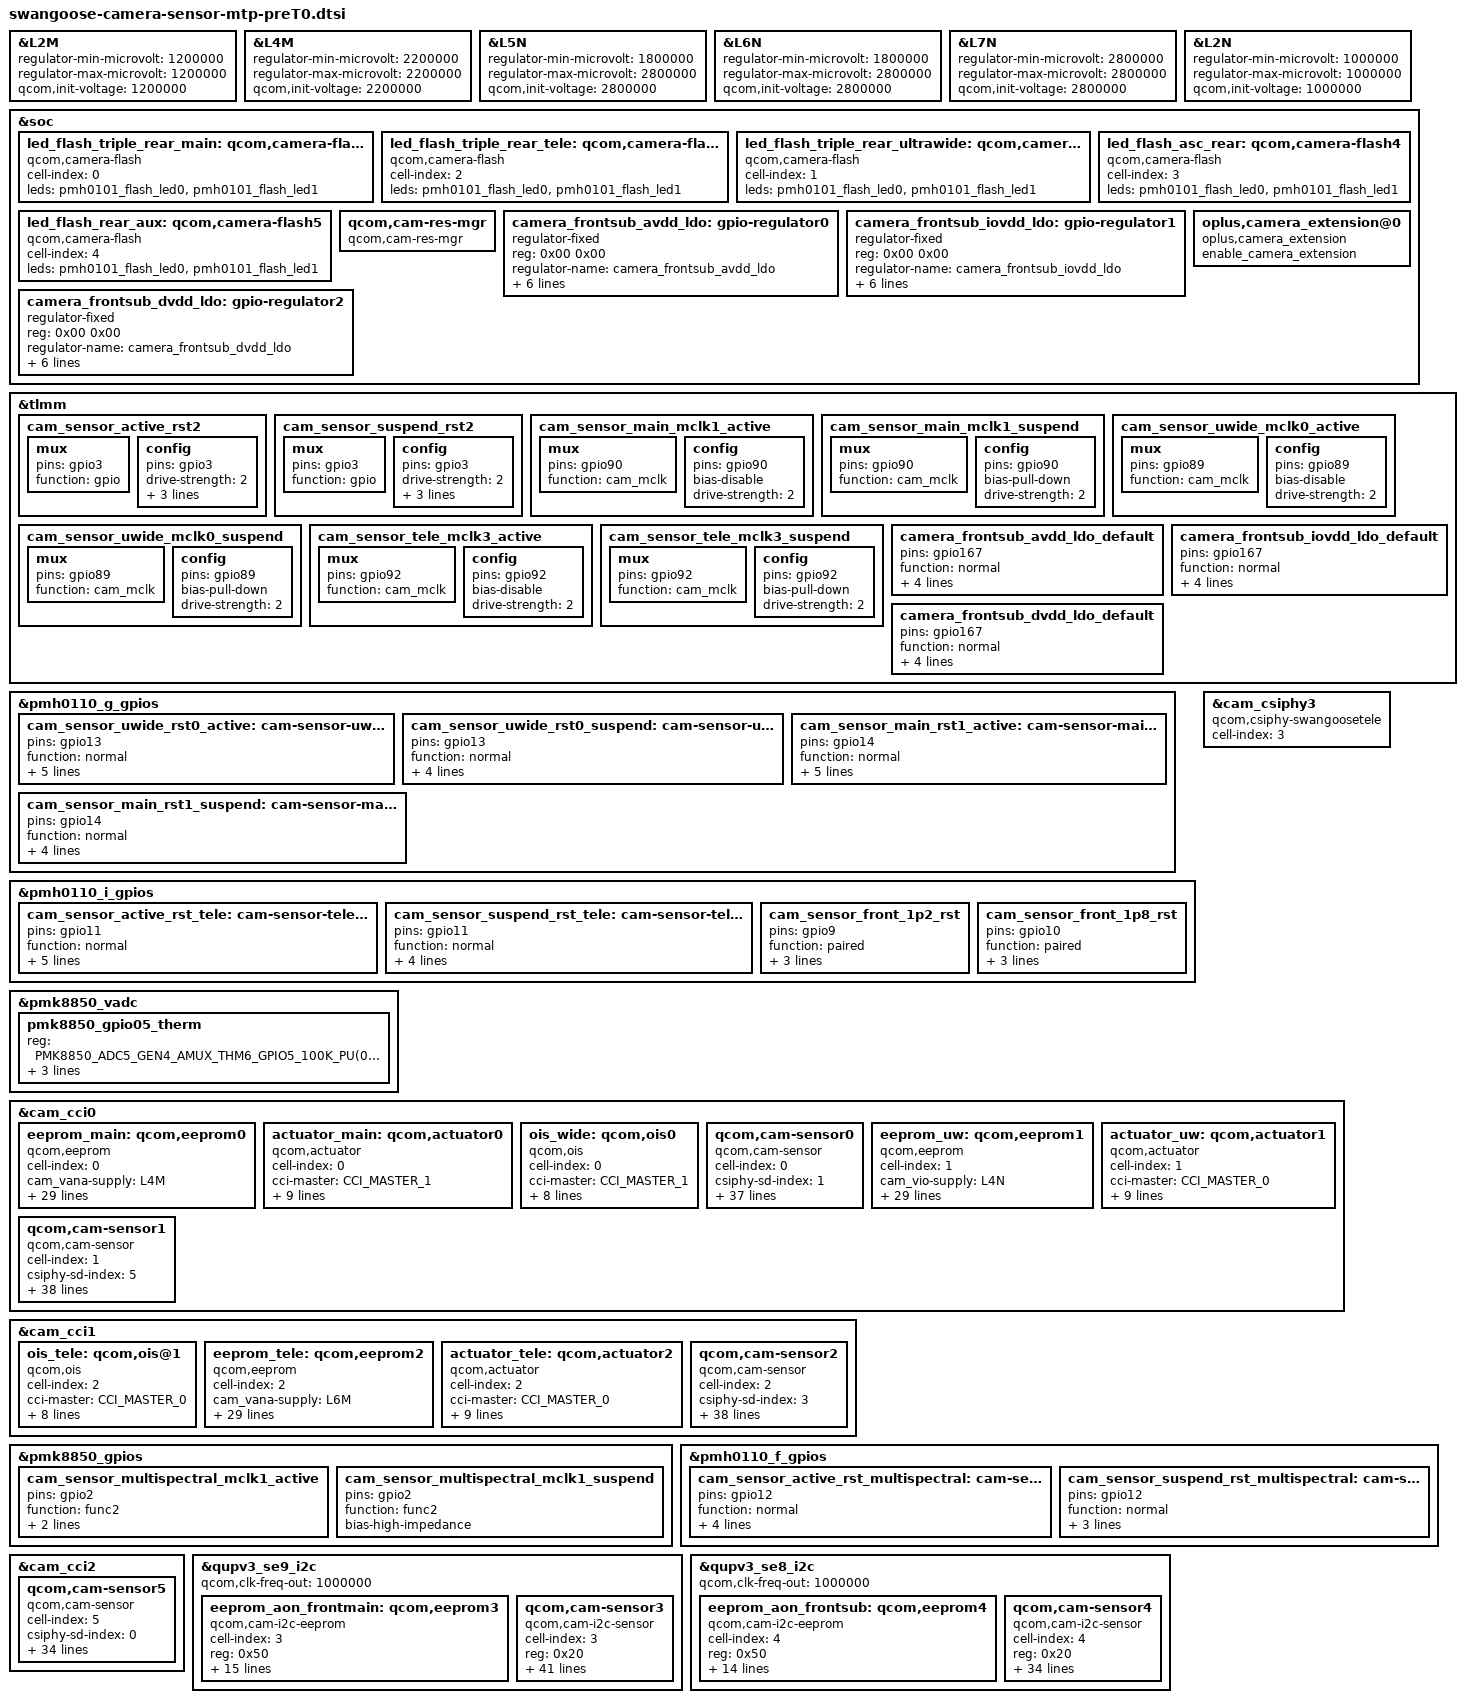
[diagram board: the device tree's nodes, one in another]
// SPDX-License-Identifier: BSD-3-Clause
/*
 * Copyright (c) 2024 Qualcomm Innovation Center, Inc. All rights reserved.
 */

#include <dt-bindings/msm-camera.h>
#include "ftm_camera_settings.dtsi"
#include <dt-bindings/iio/qcom,spmi-vadc.h>
#include <dt-bindings/iio/qcom,spmi-adc5-gen4-pmk8850.h>
#define PMK8850_SID  0

&L2M {
	regulator-min-microvolt = <1200000>;
	regulator-max-microvolt = <1200000>;
	qcom,init-voltage = <1200000>;
};

&L4M {
	regulator-min-microvolt = <2200000>;
	regulator-max-microvolt = <2200000>;
	qcom,init-voltage = <2200000>;
};

&L5N {
	regulator-min-microvolt = <1800000>;
	regulator-max-microvolt = <2800000>;
	qcom,init-voltage = <2800000>;
};

&L6N {
	regulator-min-microvolt = <1800000>;
	regulator-max-microvolt = <2800000>;
	qcom,init-voltage = <2800000>;
};

&L7N {
	regulator-min-microvolt = <2800000>;
	regulator-max-microvolt = <2800000>;
	qcom,init-voltage = <2800000>;
};

&L2N {
	regulator-min-microvolt = <1000000>;
	regulator-max-microvolt = <1000000>;
	qcom,init-voltage = <1000000>;
};

&soc {

	led_flash_triple_rear_main: qcom,camera-flash1 {
		cell-index = <0>;
		compatible = "qcom,camera-flash";
		leds = <&pmh0101_flash_led0 &pmh0101_flash_led1>;
		status = "ok";
	};

	led_flash_triple_rear_tele: qcom,camera-flash2 {
		cell-index = <2>;
		compatible = "qcom,camera-flash";
		leds = <&pmh0101_flash_led0 &pmh0101_flash_led1>;
		status = "ok";
	};

	led_flash_triple_rear_ultrawide: qcom,camera-flash3 {
		cell-index = <1>;
		compatible = "qcom,camera-flash";
		leds = <&pmh0101_flash_led0 &pmh0101_flash_led1>;
		status = "ok";
	};

	led_flash_asc_rear: qcom,camera-flash4 {
		cell-index = <3>;
		compatible = "qcom,camera-flash";
		leds = <&pmh0101_flash_led0 &pmh0101_flash_led1>;
		status = "ok";
	};

	led_flash_rear_aux: qcom,camera-flash5 {
		cell-index = <4>;
		compatible = "qcom,camera-flash";
		leds = <&pmh0101_flash_led0 &pmh0101_flash_led1>;
		status = "ok";
	};

	qcom,cam-res-mgr {
		compatible = "qcom,cam-res-mgr";
		status = "ok";
	};

	camera_frontsub_avdd_ldo: gpio-regulator0 {
		compatible = "regulator-fixed";
		reg = <0x00 0x00>;
		regulator-name = "camera_frontsub_avdd_ldo";
		regulator-min-microvolt = <2800000>;
		regulator-max-microvolt = <2800000>;
		regulator-enable-ramp-delay = <135>;
		enable-active-high;
		gpio = <&tlmm 167 0>;
		pinctrl-names = "default";
		pinctrl-0 = <&camera_frontsub_avdd_ldo_default>;
	};

	camera_frontsub_iovdd_ldo: gpio-regulator1 {
		compatible = "regulator-fixed";
		reg = <0x00 0x00>;
		regulator-name = "camera_frontsub_iovdd_ldo";
		regulator-min-microvolt = <1800000>;
		regulator-max-microvolt = <1800000>;
		regulator-enable-ramp-delay = <135>;
		enable-active-high;
		gpio = <&tlmm 167 0>;
		pinctrl-names = "default";
		pinctrl-0 = <&camera_frontsub_iovdd_ldo_default>;
	};

	camera_frontsub_dvdd_ldo: gpio-regulator2 {
		compatible = "regulator-fixed";
		reg = <0x00 0x00>;
		regulator-name = "camera_frontsub_dvdd_ldo";
		regulator-min-microvolt = <1050000>;
		regulator-max-microvolt = <1050000>;
		regulator-enable-ramp-delay = <135>;
		enable-active-high;
		gpio = <&tlmm 167 0>;
		pinctrl-names = "default";
		pinctrl-0 = <&camera_frontsub_dvdd_ldo_default>;
	};

	oplus,camera_extension@0 {
		compatible = "oplus,camera_extension";
		enable_camera_extension;
		status = "ok";
	};

};

&tlmm {

	cam_sensor_active_rst2: cam_sensor_active_rst2 {
		mux {
			pins = "gpio3";
			function = "gpio";
		};

		config {
			pins = "gpio3";
			drive-strength = <2>; /* 2 MA */
			bias-pull-down; /* PULL DOWN*/
			input-enable;
			qcom,apps;
		};
	};

	cam_sensor_suspend_rst2: cam_sensor_suspend_rst2 {
		mux {
			pins = "gpio3";
			function = "gpio";
		};

		config {
			pins = "gpio3";
			drive-strength = <2>; /* 2 MA */
			bias-pull-down; /* PULL DOWN*/
			input-enable;
			qcom,apps;
		};
	};

	cam_sensor_main_mclk1_active: cam_sensor_main_mclk1_active {
		/* MCLK1 */
		mux {
			pins = "gpio90";
			function = "cam_mclk";
		};

		config {
			pins = "gpio90";
			bias-disable; /* No PULL */
			drive-strength = <2>; /* 4 MA */
		};
	};

	cam_sensor_main_mclk1_suspend: cam_sensor_main_mclk1_suspend {
		/* MCLK1 */
		mux {
			pins = "gpio90";
			function = "cam_mclk";
		};

		config {
			pins = "gpio90";
			bias-pull-down; /* PULL DOWN */
			drive-strength = <2>; /* 4 MA */
		};
	};

	cam_sensor_uwide_mclk0_active: cam_sensor_uwide_mclk0_active {
		/* MCLK0 */
		mux {
			pins = "gpio89";
			function = "cam_mclk";
		};

		config {
			pins = "gpio89";
			bias-disable; /* No PULL */
			drive-strength = <2>; /* 2 MA */
		};
	};

	cam_sensor_uwide_mclk0_suspend: cam_sensor_uwide_mclk0_suspend {
		/* MCLK0 */
		mux {
			pins = "gpio89";
			function = "cam_mclk";
		};

		config {
			pins = "gpio89";
			bias-pull-down; /* PULL DOWN */
			drive-strength = <2>; /* 2 MA */
		};
	};

	cam_sensor_tele_mclk3_active: cam_sensor_tele_mclk3_active {
		/* MCLK3 */
		mux {
			pins = "gpio92";
			function = "cam_mclk";
		};

		config {
			pins = "gpio92";
			bias-disable; /* No PULL */
			drive-strength = <2>; /* 2 MA */
		};
	};

	cam_sensor_tele_mclk3_suspend: cam_sensor_tele_mclk3_suspend {
		/* MCLK3 */
		mux {
			pins = "gpio92";
			function = "cam_mclk";
		};

		config {
			pins = "gpio92";
			bias-pull-down; /* PULL DOWN */
			drive-strength = <2>; /* 2 MA */
		};
	};

	camera_frontsub_avdd_ldo_default: camera_frontsub_avdd_ldo_default {
		pins = "gpio167";
		function = "normal";
		input-disable;
		output-low;
		power-source = <1>; /* 2.8V */
		qcom,drive-strength = <2>;
	};

	camera_frontsub_iovdd_ldo_default: camera_frontsub_iovdd_ldo_default {
		pins = "gpio167";
		function = "normal";
		input-disable;
		output-low;
		power-source = <1>; /* 2.8V */
		qcom,drive-strength = <2>;
	};

	camera_frontsub_dvdd_ldo_default: camera_frontsub_dvdd_ldo_default {
		pins = "gpio167";
		function = "normal";
		input-disable;
		output-low;
		power-source = <1>; /* 2.8V */
		qcom,drive-strength = <2>;
	};

};

&pmh0110_g_gpios {

	cam_sensor_uwide_rst0_active: cam-sensor-uwide-rst0-active-state {
		pins = "gpio13";
		function = "normal";
		qcom,drive-strength = <2>;
		input-disable;
		output-enable;
		output-high;
		power-source = <1>; /* 1.2 V */
	};

	cam_sensor_uwide_rst0_suspend: cam-sensor-uwide-rst0-suspend-state {
		pins = "gpio13";
		function = "normal";
		qcom,drive-strength = <2>;
		input-disable;
		output-enable;
		output-low;
	};

	cam_sensor_main_rst1_active: cam-sensor-main-rst1-active-state {
		pins = "gpio14";
		function = "normal";
		qcom,drive-strength = <2>;
		input-disable;
		output-enable;
		output-high;
		power-source = <1>; /* 1.2 V */
	};

	cam_sensor_main_rst1_suspend: cam-sensor-main-rst1-suspend-state {
		pins = "gpio14";
		function = "normal";
		qcom,drive-strength = <2>;
		input-disable;
		output-enable;
		output-low;
	};
};

&pmh0110_i_gpios {

	cam_sensor_active_rst_tele: cam-sensor-tele-active-state {
		pins = "gpio11";
		function = "normal";
		qcom,drive-strength = <2>;
		input-disable;
		output-enable;
		output-high;
		power-source = <1>; /* 1.2 V */
	};

	cam_sensor_suspend_rst_tele: cam-sensor-tele-suspend-state {
		pins = "gpio11";
		function = "normal";
		qcom,drive-strength = <2>;
		input-disable;
		output-enable;
		output-low;
	};

	cam_sensor_front_1p2_rst: cam_sensor_front_1p2_rst {
		pins = "gpio9";
		function = "paired";
		input-enable;
		output-disable;
		power-source = <1>; /* 1.2v */
	};

	cam_sensor_front_1p8_rst: cam_sensor_front_1p8_rst {
		pins = "gpio10";
		function = "paired";
		input-disable;
		output-enable;
		power-source = <2>; /* 1.8v */
	};
};

&pmk8850_vadc{
	pmk8850_gpio05_therm {
		reg = <PMK8850_ADC5_GEN4_AMUX_THM6_GPIO5_100K_PU(0, PMK8850_SID)>;
		label = "pmk8850_gpio05_therm";
		qcom,ratiometric;
		qcom,hw-settle-time = <200>;
	};
};

&cam_csiphy3{
	cell-index = <3>;
	compatible = "qcom,csiphy-swangoosetele", "qcom,csiphy";
};

&cam_cci0 {

 eeprom_main: qcom,eeprom0 {
		cell-index = <0>;
		compatible = "qcom,eeprom";
		cam_vana-supply = <&L4M>;
		cam_v_custom1-supply = <&L3N>;
		cam_vdig-supply = <&L1N>;
		cam_vio-supply = <&L2M>;
		cam_vaf-supply = <&L7M>;
		power-domains = <&camcc CAM_CC_TITAN_TOP_GDSC>;
		regulator-names = "cam_vana", "cam_v_custom1", "cam_vdig", "cam_vio", "cam_vaf";
		rgltr-cntrl-support;
		rgltr-min-voltage = <2200000 1800000 1100000 1200000 2800000>;
		rgltr-max-voltage = <2200000 1800000 1100000 1200000 2800000>;
		rgltr-load-current = <300000 300000 1200000 600000 600000>;
		gpio-no-mux = <0>;
		pinctrl-names = "cam_default", "cam_suspend";
		pinctrl-0 = <&cam_sensor_main_mclk1_active
			&cam_sensor_main_rst1_active>;
		pinctrl-1 = <&cam_sensor_main_mclk1_suspend
			&cam_sensor_main_rst1_suspend>;
		gpios = <&tlmm 90 0>,
			<&pmh0110_g_gpios 14 0>;
		gpio-reset = <1>;
		gpio-req-tbl-num = <0 1>;
		gpio-req-tbl-flags = <1 0>;
		gpio-req-tbl-label = "CAMIF_MCLK1",
					"CAM_RESET1";
		cci-master = <CCI_MASTER_1>;
		clocks = <&cambistmclkcc CAM_BIST_MCLK_CC_MCLK1_CLK>;
		clock-names = "cam_clk";
		clock-cntl-level = "nominal";
		clock-rates = <19200000>;
		status = "ok";
	};

	actuator_main: qcom,actuator0{
		cell-index = <0>;
		compatible = "qcom,actuator";
		cci-master = <CCI_MASTER_1>;
		cam_vio-supply = <&L2M>;
		cam_vaf-supply = <&L7M>;
		regulator-names = "cam_vio", "cam_vaf";
		rgltr-cntrl-support;
		rgltr-min-voltage = <1200000 2800000>;
		rgltr-max-voltage = <1200000 2800000>;
		rgltr-load-current = <600000 600000>;
		actuator,name = "ak7377";
		cci_client_sid = <0x18>;
		status = "ok";
	};

	ois_wide: qcom,ois0 {
		cell-index = <0>;
		compatible = "qcom,ois";
		cci-master = <CCI_MASTER_1>;
		cam_vio-supply = <&L2M>;
		cam_vaf-supply = <&L7M>;
		power-domains = <&camcc CAM_CC_TITAN_TOP_GDSC>;
		regulator-names = "cam_vio","cam_vaf";
		rgltr-cntrl-support;
		rgltr-min-voltage = <1200000 2800000>;
		rgltr-max-voltage = <1200000 2800000>;
		rgltr-load-current = <600000 600000>;
		status = "ok";
	};


	qcom,cam-sensor0 {
		cell-index = <0>;
		compatible = "qcom,cam-sensor";
		csiphy-sd-index = <1>;
		sensor-position-roll = <90>;
		sensor-position-pitch = <0>;
		sensor-position-yaw = <180>;
		led-flash-src = <&led_flash_triple_rear_main>;
		eeprom-src = <&eeprom_main>;
		actuator-src = <&actuator_main>;
		//ois-src = <&ois_wide>;
		cam_vana-supply = <&L4M>;
		cam_v_custom1-supply = <&L3N>;
		cam_vdig-supply = <&L1N>;
		cam_vio-supply = <&L2M>;
		cam_vaf-supply = <&L7M>;
		power-domains = <&camcc CAM_CC_TITAN_TOP_GDSC>;
		regulator-names = "cam_vana", "cam_v_custom1", "cam_vdig", "cam_vio", "cam_vaf";
		rgltr-cntrl-support;
		rgltr-min-voltage = <2200000 1800000 1100000 1200000 2800000>;
		rgltr-max-voltage = <2200000 1800000 1100000 1200000 2800000>;
		rgltr-load-current = <300000 300000 1200000 600000 600000>;
		gpio-no-mux = <0>;
		pinctrl-names = "cam_default", "cam_suspend";
		pinctrl-0 = <&cam_sensor_main_mclk1_active
			&cam_sensor_main_rst1_active>;
		pinctrl-1 = <&cam_sensor_main_mclk1_suspend
			&cam_sensor_main_rst1_suspend>;
		gpios = <&tlmm 90 0>,
			<&pmh0110_g_gpios 14 0>;
		gpio-reset = <1>;
		gpio-req-tbl-num = <0 1>;
		gpio-req-tbl-flags = <1 0>;
		gpio-req-tbl-label = "CAMIF_MCLK1",
					"CAM_RESET1";
		cci-master = <CCI_MASTER_1>;
		clocks = <&cambistmclkcc CAM_BIST_MCLK_CC_MCLK1_CLK>;
		clock-names = "cam_clk";
		clock-cntl-level = "nominal";
		clock-rates = <19200000>;
		ftm_setting_compatible = <'R' 0x0000 2 2 0x1B75>; // expect camera_0000_1B75
		status = "ok";
	};


	eeprom_uw: qcom,eeprom1 {
		cell-index = <1>;
		compatible = "qcom,eeprom";
		cam_vio-supply = <&L4N>;
		cam_vdig-supply = <&L2N>;
		cam_vana-supply = <&L6M>;
		cam_vaf-supply = <&L7M>;
		cam_v_custom1-supply = <&L2M>;
		power-domains = <&camcc CAM_CC_TITAN_TOP_GDSC>;
		regulator-names = "cam_vio", "cam_vdig", "cam_vana",
			"cam_vaf", "cam_v_custom1";
		rgltr-cntrl-support;
		rgltr-min-voltage = <1800000 1000000 2200000 2800000 1200000>;
		rgltr-max-voltage = <1800000 1000000 2200000 2800000 1200000>;
		rgltr-load-current = <300000 1200000 300000 600000 600000>;
		gpio-no-mux = <0>;
		pinctrl-names = "cam_default", "cam_suspend";
		pinctrl-0 = <&cam_sensor_uwide_mclk0_active
				 &cam_sensor_uwide_rst0_active>;
		pinctrl-1 = <&cam_sensor_uwide_mclk0_suspend
				 &cam_sensor_uwide_rst0_suspend>;
		gpios = <&tlmm 89 0>,
			<&pmh0110_g_gpios 13 0>;
		gpio-reset = <1>;
		gpio-req-tbl-num = <0 1>;
		gpio-req-tbl-flags = <1 0>;
		gpio-req-tbl-label = "CAMIF_MCLK0",
					"CAM_RESET0";
		cci-master = <CCI_MASTER_0>;
		clocks = <&cambistmclkcc CAM_BIST_MCLK_CC_MCLK0_CLK>;
		clock-names = "cam_clk";
		clock-cntl-level = "nominal";
		clock-rates = <19200000>;
		status = "ok";
	};

	actuator_uw: qcom,actuator1 {
		cell-index = <1>;
		compatible = "qcom,actuator";
		cci-master = <CCI_MASTER_0>;
		cam_vio-supply = <&L4N>;
		cam_vaf-supply = <&L7M>;
		cam_v_custom1-supply = <&L2M>;
		regulator-names = "cam_vio", "cam_vaf", "cam_v_custom1";
		rgltr-cntrl-support;
		rgltr-min-voltage = <1800000 2800000 1200000>;
		rgltr-max-voltage = <1800000 2800000 1200000>;
		rgltr-load-current = <300000 600000 600000>;
		status = "ok";
	};

	//ultra wide sensor
	qcom,cam-sensor1 {
		cell-index = <1>;
		compatible = "qcom,cam-sensor";
		csiphy-sd-index = <5>;
		sensor-position-roll = <90>;
		sensor-position-pitch = <0>;
		sensor-position-yaw = <180>;
		eeprom-src = <&eeprom_uw>;
		actuator-src = <&actuator_uw>;
		led-flash-src = <&led_flash_triple_rear_ultrawide>;
		cam_vio-supply = <&L4N>;
		cam_vdig-supply = <&L2N>;
		cam_vana-supply = <&L6M>;
		power-domains = <&camcc CAM_CC_TITAN_TOP_GDSC>;
		cam_vaf-supply = <&L7M>;
		cam_v_custom1-supply = <&L2M>;
		regulator-names = "cam_vio", "cam_vdig", "cam_vana",
			"cam_vaf", "cam_v_custom1";
		rgltr-cntrl-support;
		rgltr-min-voltage = <1800000 1000000 2200000 2800000 1200000>;
		rgltr-max-voltage = <1800000 1000000 2200000 2800000 1200000>;
		rgltr-load-current = <300000 1200000 300000 600000 600000>;
		gpio-no-mux = <0>;
		pinctrl-names = "cam_default", "cam_suspend";
		pinctrl-0 = <&cam_sensor_uwide_mclk0_active
				 &cam_sensor_uwide_rst0_active>;
		pinctrl-1 = <&cam_sensor_uwide_mclk0_suspend
				 &cam_sensor_uwide_rst0_suspend>;
		gpios = <&tlmm 89 0>,
			<&pmh0110_g_gpios 13 0>;
		gpio-reset = <1>;
		gpio-req-tbl-num = <0 1>;
		gpio-req-tbl-flags = <1 0>;
		gpio-req-tbl-label = "CAMIF_MCLK0",
			"CAM_RESET0";
		cci-master = <CCI_MASTER_0>;
		clocks = <&cambistmclkcc CAM_BIST_MCLK_CC_MCLK0_CLK>;
		clock-names = "cam_clk";
		clock-cntl-level = "nominal";
		clock-rates = <19200000>;
		ftm_setting_compatible = <'W' 0xFCFC 2 2 0x4000  'R' 0x0000 2 2 0x38E5>; // expect camera_0000_38E5
		status = "ok";
	};

};

&cam_cci1 {
	// tele camera
	ois_tele: qcom,ois@1 {
		cell-index = <2>;
		compatible = "qcom,ois";
		cci-master = <CCI_MASTER_0>;
		cam_vio-supply = <&L4N>;
		cam_vaf-supply = <&L7N>;
		power-domains = <&camcc CAM_CC_TITAN_TOP_GDSC>;
		regulator-names = "cam_vio","cam_vaf";
		rgltr-cntrl-support;
		rgltr-min-voltage = <1800000 2800000>;
		rgltr-max-voltage = <1800000 2800000>;
		rgltr-load-current = <300000 60000>;
		status = "ok";
	};

	eeprom_tele: qcom,eeprom2 {
		cell-index = <2>;
		compatible = "qcom,eeprom";
		cam_vana-supply = <&L6M>;
		cam_vdig-supply = <&L1M>;
		cam_vio-supply = <&L4N>;
		cam_vaf-supply = <&L7N>;
		cam_v_custom1-supply = <&L2M>;
		power-domains = <&camcc CAM_CC_TITAN_TOP_GDSC>;
		regulator-names = "cam_vana", "cam_vdig", "cam_vio", "cam_vaf","cam_v_custom1";
		rgltr-cntrl-support;
		rgltr-min-voltage = <2200000 1000000 1800000 2800000 1200000>;
		rgltr-max-voltage = <2200000 1000000 1800000 2800000 1200000>;
		rgltr-load-current = <300000 1500000 300000 600000 600000>;
		gpio-no-mux = <0>;
		pinctrl-names = "cam_default", "cam_suspend";
		pinctrl-0 = <&cam_sensor_tele_mclk3_active
			&cam_sensor_active_rst_tele>;
		pinctrl-1 = <&cam_sensor_tele_mclk3_suspend
			&cam_sensor_suspend_rst_tele>;
		gpios = <&tlmm 92 0>,
			<&pmh0110_i_gpios 11 0>;
		gpio-reset = <1>;
		gpio-req-tbl-num = <0 1>;
		gpio-req-tbl-flags = <1 0>;
		gpio-req-tbl-label = "CAMIF_MCLK3",
					"CAM_RESET3";
		cci-master = <CCI_MASTER_0>;
		clocks = <&cambistmclkcc CAM_BIST_MCLK_CC_MCLK3_CLK>;
		clock-names = "cam_clk";
		clock-cntl-level = "nominal";
		clock-rates = <19200000>;
		status = "ok";
	};

	actuator_tele: qcom,actuator2{
		cell-index = <2>;
		compatible = "qcom,actuator";
		cci-master = <CCI_MASTER_0>;
		cam_vio-supply = <&L4N>;
		cam_vaf-supply = <&L7N>;
		cam_v_custom1-supply = <&L2M>;
		regulator-names = "cam_vio", "cam_vaf", "cam_v_custom1";
		rgltr-cntrl-support;
		rgltr-min-voltage = <1800000 2800000 1200000>;
		rgltr-max-voltage = <1800000 2800000 1200000>;
		rgltr-load-current = <300000 600000 600000>;
		status = "ok";
	};

//tele_sk5jn5
	qcom,cam-sensor2 {
		cell-index = <2>;
		compatible = "qcom,cam-sensor";
		csiphy-sd-index = <3>;
		sensor-position-roll = <90>;
		sensor-position-pitch = <0>;
		sensor-position-yaw = <180>;
		led-flash-src = <&led_flash_triple_rear_tele>;
		eeprom-src = <&eeprom_tele>;
		//ois-src = <&ois_tele>;
		actuator-src = <&actuator_tele>;
		cam_vana-supply = <&L6M>;
		cam_vdig-supply = <&L1M>;
		cam_vio-supply = <&L4N>;
		cam_vaf-supply = <&L7N>;
		cam_v_custom1-supply = <&L2M>;
		power-domains = <&camcc CAM_CC_TITAN_TOP_GDSC>;
		regulator-names = "cam_vana", "cam_vdig", "cam_vio", "cam_vaf","cam_v_custom1";
		rgltr-cntrl-support;
		rgltr-min-voltage = <2200000 1000000 1800000 2800000 1200000>;
		rgltr-max-voltage = <2200000 1000000 1800000 2800000 1200000>;
		rgltr-load-current = <300000 1500000 300000 600000 600000>;
		gpio-no-mux = <0>;
		pinctrl-names = "cam_default", "cam_suspend";
		pinctrl-0 = <&cam_sensor_tele_mclk3_active
			&cam_sensor_active_rst_tele>;
		pinctrl-1 = <&cam_sensor_tele_mclk3_suspend
			&cam_sensor_suspend_rst_tele>;
		gpios = <&tlmm 92 0>,
			<&pmh0110_i_gpios 11 0>;
		gpio-reset = <1>;
		gpio-req-tbl-num = <0 1>;
		gpio-req-tbl-flags = <1 0>;
		gpio-req-tbl-label = "CAMIF_MCLK3",
					"CAM_RESET3";
		cci-master = <CCI_MASTER_0>;
		clocks = <&cambistmclkcc CAM_BIST_MCLK_CC_MCLK3_CLK>;
		clock-names = "cam_clk";
		clock-cntl-level = "nominal";
		clock-rates = <19200000>;
		ftm_setting_compatible = <'W' 0xFCFC 2 2 0x4000  'R' 0x0000 2 2 0x38E5>; // expect camera_0000_38E5
		status = "ok";
	};

};

&pmk8850_gpios {
	cam_sensor_multispectral_mclk1_active: cam_sensor_multispectral_mclk1_active {
			pins = "gpio2";
			function = "func2";
			output-enable;
			power-source = <0>; /* 1.8 V */
   };
	cam_sensor_multispectral_mclk1_suspend: cam_sensor_multispectral_mclk1_suspend {
 			pins = "gpio2";
 			function = "func2";
 			bias-high-impedance;
   };
};

&pmh0110_f_gpios {

	cam_sensor_active_rst_multispectral: cam-sensor-multispectral-active-state {
		pins = "gpio12";
		function = "normal";
		qcom,drive-strength = <2>;
		input-disable;
		output-enable;
		power-source = <0>; /* 1.8 V */
	};

	cam_sensor_suspend_rst_multispectral: cam-sensor-multispectral-suspend-state {
		pins = "gpio12";
		function = "normal";
		qcom,drive-strength = <2>;
		input-disable;
		output-enable;
	};
};

&cam_cci2 {
	//multispectral sensor
	qcom,cam-sensor5 {
		cell-index = <5>;
		compatible = "qcom,cam-sensor";
		csiphy-sd-index = <0>;
		sensor-position-roll = <90>;
		sensor-position-pitch = <0>;
		sensor-position-yaw = <180>;
		cam_vana-supply = <&L3M>;
		cam_vio-supply = <&L4N>;
		cam_v_custom1-supply = <&L2M>;
		power-domains = <&camcc CAM_CC_TITAN_TOP_GDSC>;
		regulator-names = "cam_vana", "cam_vio", "cam_v_custom1";
		rgltr-cntrl-support;
		rgltr-min-voltage = <2800000 1800000 1200000>;
		rgltr-max-voltage = <2800000 1800000 1200000>;
		rgltr-load-current = <300000 300000 600000>;
		gpio-no-mux = <0>;
		pinctrl-names = "cam_default", "cam_suspend";
		pinctrl-0 = <&cam_sensor_multispectral_mclk1_active
				 &cam_sensor_active_rst_multispectral>;
		pinctrl-1 = <&cam_sensor_multispectral_mclk1_suspend
				 &cam_sensor_suspend_rst_multispectral>;
		gpios = <&pmh0110_f_gpios 12 0>;
		gpio-reset = <0>;
		gpio-req-tbl-num = <0>;
		gpio-req-tbl-flags = <0>;
		gpio-req-tbl-label = "CAM_RESET5";
		cci-master = <CCI_MASTER_0>;
		clocks = <&rpmhcc RPMH_DIV_CLK1>;
		clock-names = "cam_clk";
		clock-cntl-level = "nominal";
		clock-rates = <19200000>;
		ftm_setting_compatible = <'R' 0x03 1 1 0x2b>;
		reg_otp_compatible = <'W' 0xFD 1 1 0x06 0
							  'R' 0x00 1 1 16 0>;
		io-channels = <&pmk8850_vadc PMK8850_ADC5_GEN4_AMUX_THM6_GPIO5_100K_PU(0, PMK8850_SID)>;
		io-channel-names = "pmk8850_gpio05_therm_channel";
		status = "ok";
	};
};

&qupv3_se9_i2c {
	status = "ok";
//	qcom,high-perf;
	qcom,clk-freq-out = <1000000>;
//	qcom,pm-ctrl-client;

	eeprom_aon_frontmain: qcom,eeprom3 {
		cell-index = <3>;
		reg = <0x50>;
		compatible = "qcom,cam-i2c-eeprom";
		cam_vana-supply = <&L3M>;
		cam_vdig-supply = <&L1M>;
		cam_vio-supply = <&L4N>;
		cam_v_custom1-supply = <&L2M>;
		power-domains = <&camcc CAM_CC_TITAN_TOP_GDSC>;
		regulator-names = "cam_vana", "cam_vdig", "cam_vio", "cam_v_custom1";
		rgltr-cntrl-support;
		rgltr-min-voltage = <2800000 1000000 1800000 1200000>;
		rgltr-max-voltage = <2800000 1000000 1800000 1200000>;
		rgltr-load-current = <300000 1200000 300000 600000>;
		gpio-no-mux = <0>;
		pinctrl-names = "cam_default", "cam_suspend";
		// pinctrl-0 = <&cam_sensor_mclk2_active
		// 		 &cam_sensor_active_rst4
		// 		 &cam_sensor_front_1p2_rst
		// 		 &cam_sensor_front_1p8_rst>;
		// pinctrl-1 = <&cam_sensor_mclk2_suspend
		// 		 &cam_sensor_suspend_rst4>;
		// gpios = <&tlmm 91 0>,
		// 	<&tlmm 7 0>,
		// 	<&pmh0110_i_gpios 9 0>,
		// 	<&pmh0110_i_gpios 10 0>;
		// gpio-reset = <1>;
		// gpio-custom1 = <2>;
		// gpio-custom2 = <3>;
		// gpio-req-tbl-num = <0 1 2 3>;
		// gpio-req-tbl-flags = <1 0 0 0>;
		// gpio-req-tbl-label = "CAMIF_MCLK2",
		// 			"CAM_RESET4",
		// 			"CAM_FRONT_RESET1.2",
		// 			"CAM_FRONT_RESET";
		// clocks = <&cambistmclkcc CAM_BIST_MCLK_CC_MCLK2_CLK>;
		// clock-names = "cam_clk";
		// clock-cntl-level = "nominal";
		// clock-rates = <19200000>;
		status = "ok";
	};

//FrontMain_KD1
	qcom,cam-sensor3 {
		cell-index = <3>;
		reg = <0x20>;
		compatible =  "qcom,cam-i2c-sensor";
		csiphy-sd-index = <2>;
		sensor-position-roll = <270>;
		sensor-position-pitch = <0>;
		sensor-position-yaw = <180>;
		eeprom-src = <&eeprom_aon_frontmain>;
		cam_vana-supply = <&L3M>;
		cam_vdig-supply = <&L1M>;
		cam_vio-supply = <&L4N>;
		cam_v_custom1-supply = <&L2M>;
		power-domains = <&camcc CAM_CC_TITAN_TOP_GDSC>;
		regulator-names = "cam_vana", "cam_vdig", "cam_vio", "cam_v_custom1";
		rgltr-cntrl-support;
		aon-camera-id = <AON_CAM1>;
		rgltr-min-voltage = <2800000 1000000 1800000 1200000>;
		rgltr-max-voltage = <2800000 1000000 1800000 1200000>;
		rgltr-load-current = <300000 1200000 300000 600000>;
		gpio-no-mux = <0>;
		pinctrl-names = "cam_default", "cam_suspend";
		pinctrl-0 = <&cam_sensor_mclk2_active
				 &cam_sensor_active_rst4
				 &cam_sensor_front_1p2_rst
				 &cam_sensor_front_1p8_rst>;
		pinctrl-1 = <&cam_sensor_mclk2_suspend
				 &cam_sensor_suspend_rst4>;
		gpios = <&tlmm 91 0>,
			<&tlmm 7 0>,
			<&pmh0110_i_gpios 9 0>,
			<&pmh0110_i_gpios 10 0>;
		gpio-reset = <1>;
		gpio-custom1 = <2>;
		gpio-custom2 = <3>;
		gpio-req-tbl-num = <0 1 2 3>;
		gpio-req-tbl-flags = <1 0 0 0>;
		gpio-req-tbl-label = "CAMIF_MCLK2",
					"CAM_RESET4",
					"CAM_FRONT_RESET_1P2",
					"CAM_FRONT_RESET";
		clocks = <&cambistmclkcc CAM_BIST_MCLK_CC_MCLK2_CLK>;
		clock-names = "cam_clk";
		clock-cntl-level = "nominal";
		clock-rates = <19200000>;
		ftm_setting_compatible = <'R' 0x0000 2 2 0x4841>; // expect camera_0000_4841
		status = "ok";
	};

};

&qupv3_se8_i2c {
	status = "ok";
//	qcom,high-perf;
	qcom,clk-freq-out = <1000000>;
//	qcom,pm-ctrl-client;

	eeprom_aon_frontsub: qcom,eeprom4 {
		cell-index = <4>;
		reg = <0x50>;
		compatible = "qcom,cam-i2c-eeprom";
		cam_vana-supply = <&L5N>;
		cam_vdig-supply = <&L6N>;
		cam_vio-supply = <&L4N>;
		cam_v_custom1-supply = <&L2M>;
		power-domains = <&camcc CAM_CC_TITAN_TOP_GDSC>;
		regulator-names = "cam_vana", "cam_vdig", "cam_vio", "cam_v_custom1";
		rgltr-cntrl-support;
		rgltr-min-voltage = <1800000 1800000 1800000 1200000>;
		rgltr-max-voltage = <1800000 1800000 1800000 1200000>;
		rgltr-load-current = <600000 600000 300000 600000>;
		// gpio-no-mux = <0>;
		// pinctrl-names = "cam_default", "cam_suspend";
		// pinctrl-0 = <&cam_sensor_mclk4_active
		// 		 &cam_sensor_active_rst2>;
		// pinctrl-1 = <&cam_sensor_mclk4_suspend
		// 		 &cam_sensor_suspend_rst2>;
		// gpios = <&tlmm 93 0>,
		// 	<&tlmm 3 0>;
		// gpio-reset = <1>;
		// gpio-req-tbl-num = <0 1>;
		// gpio-req-tbl-flags = <1 0>;
		// gpio-req-tbl-label = "CAMIF_MCLK4",
		// 			"CAM_RESET2";
		// clocks = <&cambistmclkcc CAM_BIST_MCLK_CC_MCLK4_CLK>;
		// clock-names = "cam_clk";
		// clock-cntl-level = "nominal";
		// clock-rates = <19200000>;
		status = "ok";
	};

//FrontSub_KD1
	qcom,cam-sensor4 {
		cell-index = <4>;
		reg = <0x20>;
		compatible =  "qcom,cam-i2c-sensor";
		csiphy-sd-index = <4>;
		sensor-position-roll = <270>;
		sensor-position-pitch = <0>;
		sensor-position-yaw = <180>;
		eeprom-src = <&eeprom_aon_frontsub>;
		cam_vana-supply = <&L5N>;
		cam_vdig-supply = <&L6N>;
		cam_vio-supply = <&L4N>;
		cam_v_custom1-supply = <&L2M>;
		power-domains = <&camcc CAM_CC_TITAN_TOP_GDSC>;
		regulator-names = "cam_vana", "cam_vdig", "cam_vio", "cam_v_custom1";
		rgltr-cntrl-support;
		aon-camera-id = <AON_CAM2>;
		rgltr-min-voltage = <1800000 1800000 1800000 1200000>;
		rgltr-max-voltage = <1800000 1800000 1800000 1200000>;
		rgltr-load-current = <600000 600000 300000 600000>;
		gpio-no-mux = <0>;
		pinctrl-names = "cam_default", "cam_suspend";
		pinctrl-0 = <&cam_sensor_mclk4_active>;
		pinctrl-1 = <&cam_sensor_mclk4_suspend>;
		gpios = <&tlmm 93 0>;
		gpio-req-tbl-num = <0>;
		gpio-req-tbl-flags = <1>;
		gpio-req-tbl-label = "CAMIF_MCLK4";
		clocks = <&cambistmclkcc CAM_BIST_MCLK_CC_MCLK4_CLK>;
		clock-names = "cam_clk";
		clock-cntl-level = "nominal";
		clock-rates = <19200000>;
		ftm_setting_compatible = <'R' 0x0000 2 2 0x4841>; // expect camera_0000_4841
		rst_gpio = <3>;
		is_io_extension_sensor = <1>;
		status = "ok";
	};

};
